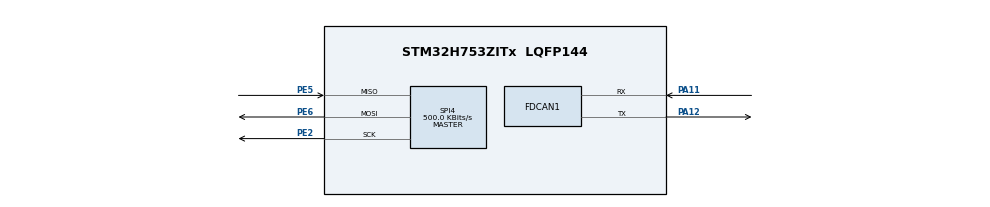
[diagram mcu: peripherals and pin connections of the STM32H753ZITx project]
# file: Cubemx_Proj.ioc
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CORTEX_M7.CPU_DCache=Disabled
CORTEX_M7.CPU_ICache=Disabled
CORTEX_M7.MPU_Control=MPU_PRIVILEGED_DEFAULT
CORTEX_M7.default_mode_Activation=1
FDCAN1.CalculateBaudRateNominal=500000
FDCAN1.CalculateTimeBitNominal=2000
FDCAN1.CalculateTimeQuantumNominal=80.0
FDCAN1.NominalPrescaler=6
FDCAN1.NominalTimeSeg1=21
FDCAN1.NominalTimeSeg2=3
FREERTOS.Tasks01=defaultTask,24,128,StartDefaultTask,Default,NULL,Dynamic,NULL,NULL;TaskIsoSPI,40,128,StartTask02,Default,NULL,Dynamic,NULL,NULL;TaskCAN,40,128,StartTask03,Default,NULL,Dynamic,NULL,NULL;TaskSOC,24,128,StartTask04,Default,NULL,Dynamic,NULL,NULL;TaskBalancing,24,128,StartTask05,Default,NULL,Dynamic,NULL,NULL;TaskDiag,8,128,StartTask06,Default,NULL,Dynamic,NULL,NULL
FREERTOS.configUSE_NEWLIB_REENTRANT=1
Mcu.Family=STM32H7
Mcu.Name=STM32H753ZITx
Mcu.Package=LQFP144
NUCLEO-H753ZI.BUTTON=1
NUCLEO-H753ZI.LD1=true
NUCLEO-H753ZI.LD2=true
NUCLEO-H753ZI.LD3=true
NUCLEO-H753ZI.VCP=true
NVIC.EXTI15_10_IRQn=true\:5\:0\:false\:false\:true\:true\:false\:true\:true
NVIC.PriorityGroup=NVIC_PRIORITYGROUP_4
NVIC.TIM7_IRQn=true\:15\:0\:false\:false\:true\:false\:false\:true\:true
NVIC.TimeBase=TIM7_IRQn
NVIC.TimeBaseIP=TIM7
PA11.Mode=FDCAN_Activate
PA11.Signal=FDCAN1_RX
PA12.Mode=FDCAN_Activate
PA12.Signal=FDCAN1_TX
PC14-OSC32_IN\ (OSC32_IN).Signal=RCC_OSC32_IN
PC15-OSC32_OUT\ (OSC32_OUT).Signal=RCC_OSC32_OUT
PD8.Signal=USART3_TX
PD9.Signal=USART3_RX
PE2.Mode=Full_Duplex_Master
PE2.Signal=SPI4_SCK
PE5.Mode=Full_Duplex_Master
PE5.Signal=SPI4_MISO
PE6.Mode=Full_Duplex_Master
PE6.Signal=SPI4_MOSI
PH0-OSC_IN\ (PH0).Signal=RCC_OSC_IN
PH1-OSC_OUT\ (PH1).Signal=RCC_OSC_OUT
ProjectManager.HeapSize=0x200
ProjectManager.StackSize=0x400
ProjectManager.TargetToolchain=STM32CubeIDE
RCC.ADCFreq_Value=129000000
RCC.APB1Freq_Value=64000000
RCC.APB2Freq_Value=64000000
RCC.APB3Freq_Value=64000000
RCC.APB4Freq_Value=64000000
RCC.CortexFreq_Value=64000000
RCC.DIVM1=4
RCC.DIVN1=9
RCC.HCLKFreq_Value=64000000
RCC.HSE_VALUE=8000000
RCC.PLLFRACN=3072
RCC.PWR_Regulator_Voltage_Scale=PWR_REGULATOR_VOLTAGE_SCALE2
RCC.SYSCLKFreq_VALUE=64000000
RCC.USBFreq_Value=75000000
SPI4.BaudRatePrescaler=SPI_BAUDRATEPRESCALER_128
SPI4.CalculateBaudRate=500.0 KBits/s
SPI4.DataSize=SPI_DATASIZE_8BIT
SPI4.Direction=SPI_DIRECTION_2LINES
SPI4.Mode=SPI_MODE_MASTER
SPI4.VirtualType=VM_MASTER
VP_FREERTOS_VS_CMSIS_V2.Mode=CMSIS_V2
VP_MEMORYMAP_VS_MEMORYMAP.Mode=CurAppReg
VP_NUCLEO-H753ZI_VS_BSP_COMMON.Mode=COMMON
VP_SYS_VS_tim7.Mode=TIM7
board=NUCLEO-H753ZI

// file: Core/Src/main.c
/* USER CODE BEGIN Header */
/**
  ******************************************************************************
  * @file           : main.c
  * @brief          : Main program body
  ******************************************************************************
  * @attention
  *
  * Copyright (c) 2026 STMicroelectronics.
  * All rights reserved.
  *
  * This software is licensed under terms that can be found in the LICENSE file
  * in the root directory of this software component.
  * If no LICENSE file comes with this software, it is provided AS-IS.
  *
  ******************************************************************************
  */
/* USER CODE END Header */
#include "main.h"
#include "FreeRTOS.h"
#include "cmsis_os2.h"
#include "fdcan.h"
#include "spi.h"
#include "gpio.h"

COM_InitTypeDef BspCOMInit;

void SystemClock_Config(void);
static void MPU_Config(void);
void MX_FREERTOS_Init(void);

int main(void)
{

  /* MPU Configuration--------------------------------------------------------*/
  MPU_Config();

  /* MCU Configuration--------------------------------------------------------*/

  /* Reset of all peripherals, Initializes the Flash interface and the Systick. */
  HAL_Init();

  /* Configure the system clock */
  SystemClock_Config();

  /* Initialize all configured peripherals */
  MX_GPIO_Init();
  MX_FDCAN1_Init();
  MX_SPI4_Init();

  /* Init scheduler */
  osKernelInitialize();  /* Call init function for freertos objects (in cmsis_os2.c) */
  MX_FREERTOS_Init();

  /* Initialize leds */
  BSP_LED_Init(LED_GREEN);
  BSP_LED_Init(LED_YELLOW);
  BSP_LED_Init(LED_RED);

  /* Initialize USER push-button, will be used to trigger an interrupt each time it's pressed.*/
  BSP_PB_Init(BUTTON_USER, BUTTON_MODE_EXTI);

  /* Initialize COM1 port (115200, 8 bits (7-bit data + 1 stop bit), no parity */
  BspCOMInit.BaudRate   = 115200;
  BspCOMInit.WordLength = COM_WORDLENGTH_8B;
  BspCOMInit.StopBits   = COM_STOPBITS_1;
  BspCOMInit.Parity     = COM_PARITY_NONE;
  BspCOMInit.HwFlowCtl  = COM_HWCONTROL_NONE;
  if (BSP_COM_Init(COM1, &BspCOMInit) != BSP_ERROR_NONE)
  {
    Error_Handler();
  }

  /* Start scheduler */
  osKernelStart();

  /* We should never get here as control is now taken by the scheduler */

  /* Infinite loop */
  while (1)
  {

  }
}

void SystemClock_Config(void)
{
  RCC_OscInitTypeDef RCC_OscInitStruct = {0};
  RCC_ClkInitTypeDef RCC_ClkInitStruct = {0};

  /** Supply configuration update enable
  */
  HAL_PWREx_ConfigSupply(PWR_LDO_SUPPLY);

  /** Configure the main internal regulator output voltage
  */
  __HAL_PWR_VOLTAGESCALING_CONFIG(PWR_REGULATOR_VOLTAGE_SCALE2);

  while(!__HAL_PWR_GET_FLAG(PWR_FLAG_VOSRDY)) {}

  /** Initializes the RCC Oscillators according to the specified parameters
  * in the RCC_OscInitTypeDef structure.
  */
  RCC_OscInitStruct.OscillatorType = RCC_OSCILLATORTYPE_HSI;
  RCC_OscInitStruct.HSIState = RCC_HSI_DIV1;
  RCC_OscInitStruct.HSICalibrationValue = RCC_HSICALIBRATION_DEFAULT;
  RCC_OscInitStruct.PLL.PLLState = RCC_PLL_ON;
  RCC_OscInitStruct.PLL.PLLSource = RCC_PLLSOURCE_HSI;
  RCC_OscInitStruct.PLL.PLLM = 4;
  RCC_OscInitStruct.PLL.PLLN = 9;
  RCC_OscInitStruct.PLL.PLLP = 2;
  RCC_OscInitStruct.PLL.PLLQ = 2;
  RCC_OscInitStruct.PLL.PLLR = 2;
  RCC_OscInitStruct.PLL.PLLRGE = RCC_PLL1VCIRANGE_3;
  RCC_OscInitStruct.PLL.PLLVCOSEL = RCC_PLL1VCOMEDIUM;
  RCC_OscInitStruct.PLL.PLLFRACN = 3072;
  if (HAL_RCC_OscConfig(&RCC_OscInitStruct) != HAL_OK)
  {
    Error_Handler();
  }

  /** Initializes the CPU, AHB and APB buses clocks
  */
  RCC_ClkInitStruct.ClockType = RCC_CLOCKTYPE_HCLK|RCC_CLOCKTYPE_SYSCLK
                              |RCC_CLOCKTYPE_PCLK1|RCC_CLOCKTYPE_PCLK2
                              |RCC_CLOCKTYPE_D3PCLK1|RCC_CLOCKTYPE_D1PCLK1;
  RCC_ClkInitStruct.SYSCLKSource = RCC_SYSCLKSOURCE_HSI;
  RCC_ClkInitStruct.SYSCLKDivider = RCC_SYSCLK_DIV1;
  RCC_ClkInitStruct.AHBCLKDivider = RCC_HCLK_DIV1;
  RCC_ClkInitStruct.APB3CLKDivider = RCC_APB3_DIV1;
  RCC_ClkInitStruct.APB1CLKDivider = RCC_APB1_DIV1;
  RCC_ClkInitStruct.APB2CLKDivider = RCC_APB2_DIV1;
  RCC_ClkInitStruct.APB4CLKDivider = RCC_APB4_DIV1;

  if (HAL_RCC_ClockConfig(&RCC_ClkInitStruct, FLASH_LATENCY_1) != HAL_OK)
  {
    Error_Handler();
  }
}

 /* MPU Configuration */

void MPU_Config(void)
{
  MPU_Region_InitTypeDef MPU_InitStruct = {0};

  /* Disables the MPU */
  HAL_MPU_Disable();

  /** Initializes and configures the Region and the memory to be protected
  */
  MPU_InitStruct.Enable = MPU_REGION_ENABLE;
  MPU_InitStruct.Number = MPU_REGION_NUMBER0;
  MPU_InitStruct.BaseAddress = 0x0;
  MPU_InitStruct.Size = MPU_REGION_SIZE_4GB;
  MPU_InitStruct.SubRegionDisable = 0x87;
  MPU_InitStruct.TypeExtField = MPU_TEX_LEVEL0;
  MPU_InitStruct.AccessPermission = MPU_REGION_NO_ACCESS;
  MPU_InitStruct.DisableExec = MPU_INSTRUCTION_ACCESS_DISABLE;
  MPU_InitStruct.IsShareable = MPU_ACCESS_SHAREABLE;
  MPU_InitStruct.IsCacheable = MPU_ACCESS_NOT_CACHEABLE;
  MPU_InitStruct.IsBufferable = MPU_ACCESS_NOT_BUFFERABLE;

  HAL_MPU_ConfigRegion(&MPU_InitStruct);
  /* Enables the MPU */
  HAL_MPU_Enable(MPU_PRIVILEGED_DEFAULT);

}

void HAL_TIM_PeriodElapsedCallback(TIM_HandleTypeDef *htim)
{
  if (htim->Instance == TIM7)
  {
    HAL_IncTick();
  }
}

void Error_Handler(void)
{
  __disable_irq();
  while (1)
  {
  }
}

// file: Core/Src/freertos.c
/* USER CODE BEGIN Header */
/**
  ******************************************************************************
  * File Name          : freertos.c
  * Description        : Code for freertos applications
  ******************************************************************************
  * @attention
  *
  * Copyright (c) 2026 STMicroelectronics.
  * All rights reserved.
  *
  * This software is licensed under terms that can be found in the LICENSE file
  * in the root directory of this software component.
  * If no LICENSE file comes with this software, it is provided AS-IS.
  *
  ******************************************************************************
  */
/* USER CODE END Header */

#include "FreeRTOS.h"
#include "task.h"
#include "main.h"
#include "FreeRTOS.h"
#include "cmsis_os2.h"

/* Definitions for defaultTask */
osThreadId_t defaultTaskHandle;
const osThreadAttr_t defaultTask_attributes = {
  .name = "defaultTask",
  .stack_size = 128 * 4,
  .priority = (osPriority_t) osPriorityNormal,
};
/* Definitions for TaskIsoSPI */
osThreadId_t TaskIsoSPIHandle;
const osThreadAttr_t TaskIsoSPI_attributes = {
  .name = "TaskIsoSPI",
  .stack_size = 128 * 4,
  .priority = (osPriority_t) osPriorityHigh,
};
/* Definitions for TaskCAN */
osThreadId_t TaskCANHandle;
const osThreadAttr_t TaskCAN_attributes = {
  .name = "TaskCAN",
  .stack_size = 128 * 4,
  .priority = (osPriority_t) osPriorityHigh,
};
/* Definitions for TaskSOC */
osThreadId_t TaskSOCHandle;
const osThreadAttr_t TaskSOC_attributes = {
  .name = "TaskSOC",
  .stack_size = 128 * 4,
  .priority = (osPriority_t) osPriorityNormal,
};
/* Definitions for TaskBalancing */
osThreadId_t TaskBalancingHandle;
const osThreadAttr_t TaskBalancing_attributes = {
  .name = "TaskBalancing",
  .stack_size = 128 * 4,
  .priority = (osPriority_t) osPriorityNormal,
};
/* Definitions for TaskDiag */
osThreadId_t TaskDiagHandle;
const osThreadAttr_t TaskDiag_attributes = {
  .name = "TaskDiag",
  .stack_size = 128 * 4,
  .priority = (osPriority_t) osPriorityLow,
};

void StartDefaultTask(void *argument);
void StartTask02(void *argument);
void StartTask03(void *argument);
void StartTask04(void *argument);
void StartTask05(void *argument);
void StartTask06(void *argument);

void MX_FREERTOS_Init(void); /* (MISRA C 2004 rule 8.1) */

void MX_FREERTOS_Init(void) {

  /* Create the thread(s) */
  /* creation of defaultTask */
  defaultTaskHandle = osThreadNew(StartDefaultTask, NULL, &defaultTask_attributes);

  /* creation of TaskIsoSPI */
  TaskIsoSPIHandle = osThreadNew(StartTask02, NULL, &TaskIsoSPI_attributes);

  /* creation of TaskCAN */
  TaskCANHandle = osThreadNew(StartTask03, NULL, &TaskCAN_attributes);

  /* creation of TaskSOC */
  TaskSOCHandle = osThreadNew(StartTask04, NULL, &TaskSOC_attributes);

  /* creation of TaskBalancing */
  TaskBalancingHandle = osThreadNew(StartTask05, NULL, &TaskBalancing_attributes);

  /* creation of TaskDiag */
  TaskDiagHandle = osThreadNew(StartTask06, NULL, &TaskDiag_attributes);

}

void StartDefaultTask(void *argument)
{
  for(;;)
  {
    osDelay(1);
  }
}

void StartTask02(void *argument)
{
  for(;;)
  {
    osDelay(1);
  }
}

void StartTask03(void *argument)
{
  for(;;)
  {
    osDelay(1);
  }
}

void StartTask04(void *argument)
{
  for(;;)
  {
    osDelay(1);
  }
}

void StartTask05(void *argument)
{
  for(;;)
  {
    osDelay(1);
  }
}

void StartTask06(void *argument)
{
  /* USER CODE BEGIN StartTask06 */

  /* Infinite loop */
  for(;;)
  {
	    HAL_GPIO_TogglePin(LED1_GPIO_PORT, LED1_PIN);
	    osDelay(500);
  }
  /* USER CODE END StartTask06 */
}
